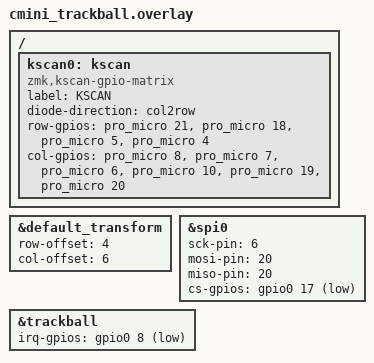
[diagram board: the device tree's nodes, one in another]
#include "cmini.dtsi"

&default_transform {
    row-offset = <4>;
    col-offset = <6>;
};

/ {
    kscan0: kscan {
        compatible = "zmk,kscan-gpio-matrix";
        label = "KSCAN";
        diode-direction = "col2row";

        row-gpios
        = <&pro_micro 21 (GPIO_ACTIVE_HIGH | GPIO_PULL_DOWN)>
        , <&pro_micro 18 (GPIO_ACTIVE_HIGH | GPIO_PULL_DOWN)>
        , <&pro_micro 5 (GPIO_ACTIVE_HIGH | GPIO_PULL_DOWN)>
        , <&pro_micro 4 (GPIO_ACTIVE_HIGH | GPIO_PULL_DOWN)>
        ;
    col-gpios
        = <&pro_micro 8 GPIO_ACTIVE_HIGH>
        , <&pro_micro 7 GPIO_ACTIVE_HIGH>
        , <&pro_micro 6 GPIO_ACTIVE_HIGH>
        , <&pro_micro 10 GPIO_ACTIVE_HIGH>
        , <&pro_micro 19 GPIO_ACTIVE_HIGH>
        , <&pro_micro 20 GPIO_ACTIVE_HIGH>
        ;
    };
};


&spi0 {
  status = "okay";
  sck-pin = <6>;
  mosi-pin = <20>;
  miso-pin = <20>; // same as mosi (3-wire spi)
  cs-gpios = <&gpio0 17 GPIO_ACTIVE_LOW>;
};

&trackball {
  status = "okay";
  irq-gpios = <&gpio0 8 (GPIO_ACTIVE_LOW | GPIO_PULL_UP)>;
};

